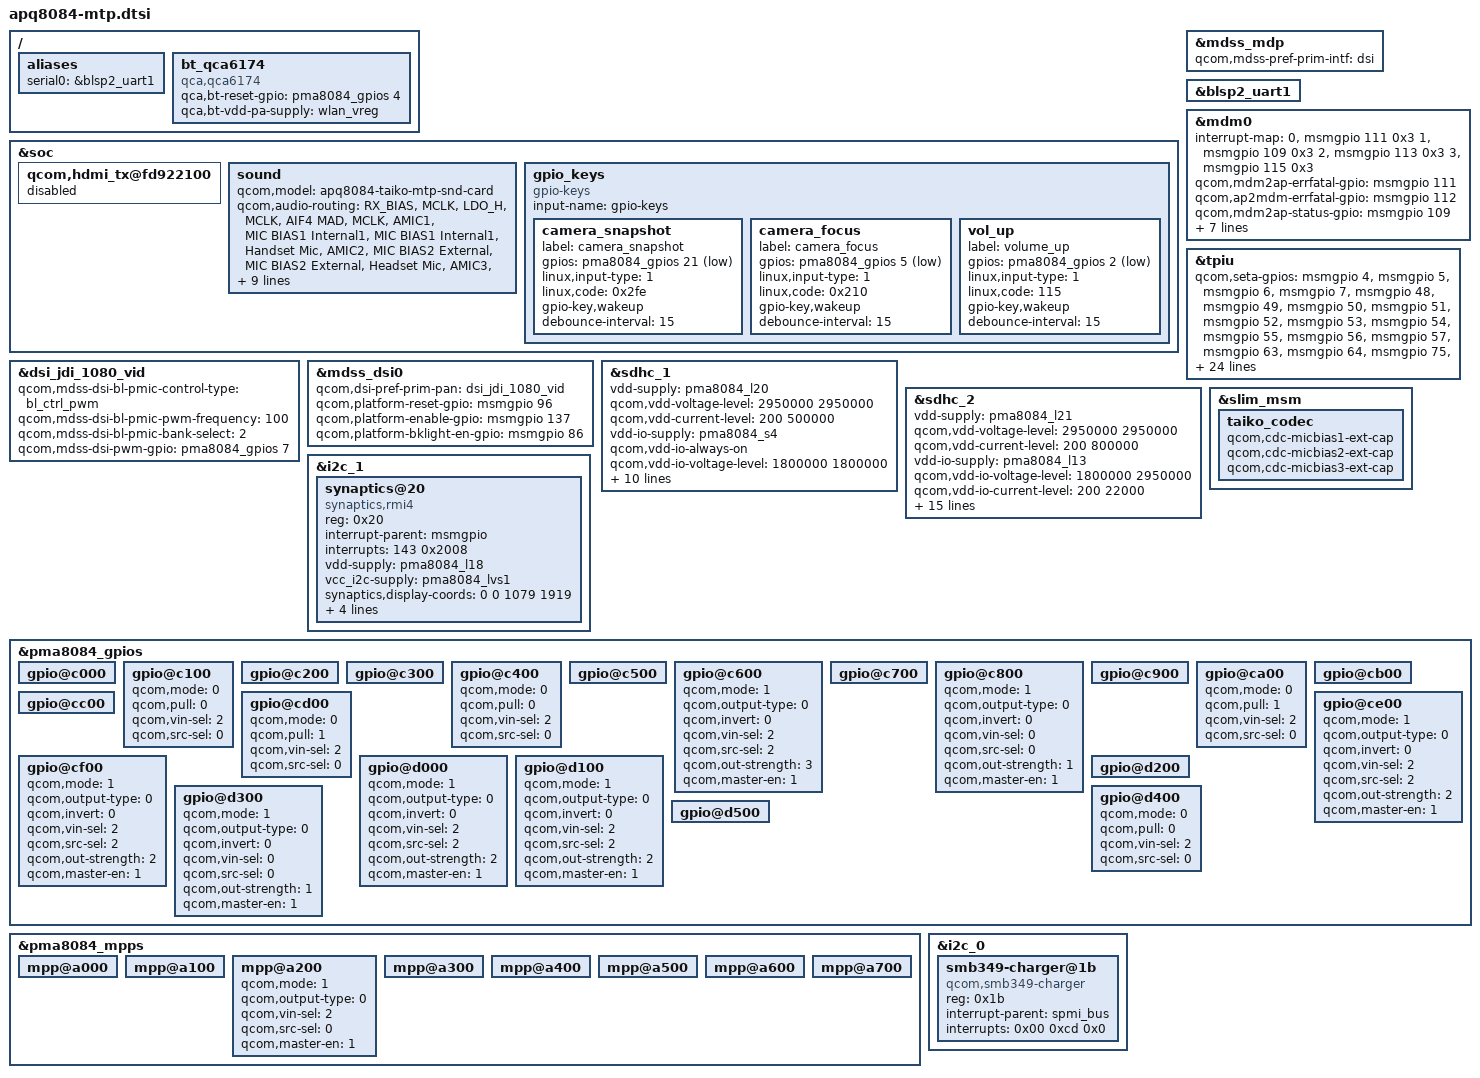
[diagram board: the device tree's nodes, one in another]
/* Copyright (c) 2013, The Linux Foundation. All rights reserved.
 *
 * This program is free software; you can redistribute it and/or modify
 * it under the terms of the GNU General Public License version 2 and
 * only version 2 as published by the Free Software Foundation.
 *
 * This program is distributed in the hope that it will be useful,
 * but WITHOUT ANY WARRANTY; without even the implied warranty of
 * MERCHANTABILITY or FITNESS FOR A PARTICULAR PURPOSE.  See the
 * GNU General Public License for more details.
 */

/include/ "external-mdm9x25.dtsi"

/ {
	aliases {
		serial0 = &blsp2_uart1;
	};

	bt_qca6174 {
		compatible = "qca,qca6174";
		qca,bt-reset-gpio = <&pma8084_gpios 4 0>; /* BT_EN */
		qca,bt-vdd-pa-supply = <&wlan_vreg>;
	};
};

&soc {
	qcom,hdmi_tx@fd922100 {
		status = "disabled";
	};

	sound {
		qcom,model = "apq8084-taiko-mtp-snd-card";

		qcom,audio-routing =
			"RX_BIAS", "MCLK",
			"LDO_H", "MCLK",
			"AIF4 MAD", "MCLK",
			"AMIC1", "MIC BIAS1 Internal1",
			"MIC BIAS1 Internal1", "Handset Mic",
			"AMIC2", "MIC BIAS2 External",
			"MIC BIAS2 External", "Headset Mic",
			"AMIC3", "MIC BIAS2 External",
			"MIC BIAS2 External", "ANCRight Headset Mic",
			"AMIC4", "MIC BIAS2 External",
			"MIC BIAS2 External", "ANCLeft Headset Mic",
			"DMIC1", "MIC BIAS1 External",
			"MIC BIAS1 External", "Digital Mic1",
			"DMIC3", "MIC BIAS3 External",
			"MIC BIAS3 External", "Digital Mic3";

		qcom,cdc-micbias2-headset-only;
		qcom,ext-mclk-gpio  = <&msmgpio 47 0>;
	};

	gpio_keys {
		compatible = "gpio-keys";
		input-name = "gpio-keys";

		camera_snapshot {
			label = "camera_snapshot";
			gpios = <&pma8084_gpios 21 0x1>;
			linux,input-type = <1>;
			linux,code = <0x2fe>;
			gpio-key,wakeup;
			debounce-interval = <15>;
		};

		camera_focus {
			label = "camera_focus";
			gpios = <&pma8084_gpios 5 0x1>;
			linux,input-type = <1>;
			linux,code = <0x210>;
			gpio-key,wakeup;
			debounce-interval = <15>;
		};

		vol_up {
			label = "volume_up";
			gpios = <&pma8084_gpios 2 0x1>;
			linux,input-type = <1>;
			linux,code = <115>;
			gpio-key,wakeup;
			debounce-interval = <15>;
		};
	};
};

/include/ "dsi-panel-jdi-1080p-video.dtsi"
&dsi_jdi_1080_vid {
	qcom,mdss-dsi-bl-pmic-control-type = "bl_ctrl_pwm";
	qcom,mdss-dsi-bl-pmic-pwm-frequency = <100>;
	qcom,mdss-dsi-bl-pmic-bank-select = <2>;
	qcom,mdss-dsi-pwm-gpio = <&pma8084_gpios 7 0>;
};

&mdss_mdp {
	qcom,mdss-pref-prim-intf = "dsi";
};

&mdss_dsi0 {
	qcom,dsi-pref-prim-pan = <&dsi_jdi_1080_vid>;
	qcom,platform-reset-gpio = <&msmgpio 96 0>;
	qcom,platform-enable-gpio = <&msmgpio 137 0>;
	qcom,platform-bklight-en-gpio = <&msmgpio 86 0>;
};

&blsp2_uart1 {
	status = "ok";
};

&mdm0 {
	interrupt-map = <0 &msmgpio 111 0x3
			1 &msmgpio 109 0x3
			2 &msmgpio 113 0x3
			3 &msmgpio 115 0x3>;
	qcom,mdm2ap-errfatal-gpio = <&msmgpio 111 0x00>;
	qcom,ap2mdm-errfatal-gpio = <&msmgpio 112 0x00>;
	qcom,mdm2ap-status-gpio   = <&msmgpio 109 0x00>;
	qcom,ap2mdm-status-gpio   = <&msmgpio 110 0x00>;
	qcom,ap2mdm-soft-reset-gpio = <&msmgpio 128 0x00>;
	qcom,mdm2ap-pblrdy-gpio = <&msmgpio 113 0x00>;
	qcom,ap2mdm-wakeup-gpio = <&msmgpio 108 0x00>;
	qcom,ap2mdm-vddmin-gpio = <&msmgpio 114 0x00>;
	qcom,mdm2ap-vddmin-gpio = <&msmgpio 115 0x00>;
	qcom,ap2mdm-chnlrdy-gpio = <&msmgpio 106 0x00>;
	status = "ok";
};

/* CoreSight */
&tpiu {
	qcom,seta-gpios = <&msmgpio 4 0>,
			  <&msmgpio 5 0>,
			  <&msmgpio 6 0>,
			  <&msmgpio 7 0>,
			  <&msmgpio 48 0>,
			  <&msmgpio 49 0>,
			  <&msmgpio 50 0>,
			  <&msmgpio 51 0>,
			  <&msmgpio 52 0>,
			  <&msmgpio 53 0>,
			  <&msmgpio 54 0>,
			  <&msmgpio 55 0>,
			  <&msmgpio 56 0>,
			  <&msmgpio 57 0>,
			  <&msmgpio 63 0>,
			  <&msmgpio 64 0>,
			  <&msmgpio 75 0>,
			  <&msmgpio 122 0>;
	qcom,seta-gpios-func = <4 4 4 4 5 4 4 5 5 4 4 4 4 4 4 5 2 1>;
	qcom,seta-gpios-drv =  <7 7 7 7 7 7 7 7 7 7 7 7 7 7 7 7 7 7>;
	qcom,seta-gpios-pull = <0 0 0 0 0 0 0 0 0 0 0 0 0 0 0 0 0 0>;
	qcom,seta-gpios-dir =  <2 2 2 2 2 2 2 2 2 2 2 2 2 2 2 2 2 2>;

	qcom,setb-gpios = <&msmgpio 10 0>,
			  <&msmgpio 11 0>,
			  <&msmgpio 29 0>,
			  <&msmgpio 30 0>,
			  <&msmgpio 39 0>,
			  <&msmgpio 40 0>,
			  <&msmgpio 43 0>,
			  <&msmgpio 44 0>,
			  <&msmgpio 45 0>,
			  <&msmgpio 46 0>,
			  <&msmgpio 67 0>,
			  <&msmgpio 68 0>,
			  <&msmgpio 69 0>,
			  <&msmgpio 70 0>,
			  <&msmgpio 71 0>,
			  <&msmgpio 72 0>,
			  <&msmgpio 102 0>,
			  <&msmgpio 121 0>;
	qcom,setb-gpios-func = <4 4 5 4 4 4 4 4 4 4 3 3 2 4 3 3 2 1>;
	qcom,setb-gpios-drv =  <7 7 7 7 7 7 7 7 7 7 7 7 7 7 7 7 7 7>;
	qcom,setb-gpios-pull = <0 0 0 0 0 0 0 0 0 0 0 0 0 0 0 0 0 0>;
	qcom,setb-gpios-dir =  <2 2 2 2 2 2 2 2 2 2 2 2 2 2 2 2 2 2>;
};

&sdhc_1 {
	vdd-supply = <&pma8084_l20>;
	qcom,vdd-voltage-level = <2950000 2950000>;
	qcom,vdd-current-level = <200 500000>;

	vdd-io-supply = <&pma8084_s4>;
	qcom,vdd-io-always-on;
	qcom,vdd-io-voltage-level = <1800000 1800000>;
	qcom,vdd-io-current-level = <200 154000>;

	qcom,pad-pull-on = <0x0 0x3 0x3 0x1>; /* no-pull, pull-up, pull-up, pull-down */
	qcom,pad-pull-off = <0x0 0x3 0x3 0x1>; /* no-pull, pull-up, pull-up, pull-down */
	qcom,pad-drv-on = <0x7 0x4 0x4>; /* 16mA, 10mA, 10mA */
	qcom,pad-drv-off = <0x0 0x0 0x0>; /* 2mA, 2mA, 2mA */

	qcom,clk-rates = <400000 20000000 25000000 50000000 100000000 200000000 400000000>;
	qcom,nonremovable;
	qcom,bus-speed-mode = "HS400_1p8v", "HS200_1p8v", "DDR_1p8v";
	status = "ok";
};

&sdhc_2 {
	vdd-supply = <&pma8084_l21>;
	qcom,vdd-voltage-level = <2950000 2950000>;
	qcom,vdd-current-level = <200 800000>;

	vdd-io-supply = <&pma8084_l13>;
	qcom,vdd-io-voltage-level = <1800000 2950000>;
	qcom,vdd-io-current-level = <200 22000>;

	qcom,pad-pull-on = <0x0 0x3 0x3>; /* no-pull, pull-up, pull-up */
	qcom,pad-pull-off = <0x0 0x3 0x3>; /* no-pull, pull-up, pull-up */
	qcom,pad-drv-on = <0x7 0x4 0x4>; /* 16mA, 10mA, 10mA */
	qcom,pad-drv-off = <0x0 0x0 0x0>; /* 2mA, 2mA, 2mA */

	qcom,clk-rates = <400000 20000000 25000000 50000000 100000000 200000000>;
	qcom,bus-speed-mode = "SDR12", "SDR25", "SDR50", "DDR50", "SDR104";

	#address-cells = <0>;
	interrupt-parent = <&sdhc_2>;
	interrupts = <0 1 2>;
	#interrupt-cells = <1>;
	interrupt-map-mask = <0xffffffff>;
	interrupt-map = <0 &intc 0 125 0
			1 &intc 0 221 0
			2 &msmgpio 122 0x3>;
	interrupt-names = "hc_irq", "pwr_irq", "status_irq";
	cd-gpios = <&msmgpio 122 0x1>;
	wp-gpios = <&msmgpio 75 0x1>;

	status = "ok";
};

&slim_msm {
	taiko_codec {
		qcom,cdc-micbias1-ext-cap;
		qcom,cdc-micbias2-ext-cap;
		qcom,cdc-micbias3-ext-cap;
	};
};

&i2c_1 {
	synaptics@20 {
		compatible = "synaptics,rmi4";
		reg = <0x20>;
		interrupt-parent = <&msmgpio>;
		interrupts = <143 0x2008>;
		vdd-supply = <&pma8084_l18>;
		vcc_i2c-supply = <&pma8084_lvs1>;
		synaptics,display-coords = <0 0 1079 1919>;
		synaptics,panel-coords = <0 0 1079 2084>;
		synaptics,reset-gpio = <&msmgpio 145 0x00>;
		synaptics,irq-gpio = <&msmgpio 143 0x2008>;
		synaptics,i2c-pull-up;
	};
};

&pma8084_gpios {
	gpio@c000 { /* GPIO 1 */
	};

	gpio@c100 { /* GPIO 2 */
		qcom,mode = <0>;
		qcom,pull = <0>;
		qcom,vin-sel = <2>;
		qcom,src-sel = <0>;
	};

	gpio@c200 { /* GPIO 3 */
	};

	gpio@c300 { /* GPIO 4 */
	};

	gpio@c400 { /* GPIO 5 */
		qcom,mode = <0>;
		qcom,pull = <0>;
		qcom,vin-sel = <2>;
		qcom,src-sel = <0>;
	};

	gpio@c500 { /* GPIO 6 */
	};

	gpio@c600 { /* GPIO 7 */
		/* Backlight PWM */
		qcom,mode = <1>;		/* Digital output */
		qcom,output-type = <0>;		/* CMOS logic */
		qcom,invert = <0>;		/* Do not invert the output */
		qcom,vin-sel = <2>;		/* PMA8084 S4 = 1.8 V */
		qcom,src-sel = <2>;		/* Special Function 1=LPG 3 */
		qcom,out-strength = <3>;	/* High drive strength */
		qcom,master-en = <1>;
	};

	gpio@c700 { /* GPIO 8 */
	};

	gpio@c800 { /* GPIO 9 */
		qcom,mode = <1>;		/* Digital output */
		qcom,output-type = <0>;		/* CMOS logic */
		qcom,invert = <0>;		/* Do not invert the output */
		qcom,vin-sel = <0>;		/* VPH_PWR */
		qcom,src-sel = <0>;		/* GPIO */
		qcom,out-strength = <1>;	/* High drive strength */
		qcom,master-en = <1>;		/* Enable GPIO */
	};

	gpio@c900 { /* GPIO 10 */
	};

	gpio@ca00 { /* GPIO 11 */
		/* VBUS interrupt */
		qcom,mode = <0>;
		qcom,pull = <1>;
		qcom,vin-sel = <2>;
		qcom,src-sel = <0>;
	};

	gpio@cb00 { /* GPIO 12 */
	};

	gpio@cc00 { /* GPIO 13 */
	};

	gpio@cd00 { /* GPIO 14 */
		qcom,mode = <0>;
		qcom,pull = <1>;
		qcom,vin-sel = <2>;
		qcom,src-sel = <0>;
	};

	gpio@ce00 { /* GPIO 15 */
		qcom,mode = <1>;		/* Digital output */
		qcom,output-type = <0>;		/* CMOS logic */
		qcom,invert = <0>;		/* Output low initially */
		qcom,vin-sel = <2>;		/* VIN 2 */
		qcom,src-sel = <2>;		/* Function 1 */
		qcom,out-strength = <2>;	/* Medium */
		qcom,master-en = <1>;		/* Enable GPIO */
	};

	gpio@cf00 { /* GPIO 16 */
		qcom,mode = <1>;		/* Digital output */
		qcom,output-type = <0>;		/* CMOS logic */
		qcom,invert = <0>;		/* Output low initially */
		qcom,vin-sel = <2>;		/* VIN 2 */
		qcom,src-sel = <2>;		/* Function 1 */
		qcom,out-strength = <2>;	/* Medium */
		qcom,master-en = <1>;		/* Enable GPIO */
	};

	gpio@d000 { /* GPIO 17 */
		qcom,mode = <1>;		/* Digital output */
		qcom,output-type = <0>;		/* CMOS logic */
		qcom,invert = <0>;		/* Output low initially */
		qcom,vin-sel = <2>;		/* VIN 2 */
		qcom,src-sel = <2>;		/* Function 1 */
		qcom,out-strength = <2>;	/* Medium */
		qcom,master-en = <1>;		/* Enable GPIO */
	};

	gpio@d100 { /* GPIO 18 */
		qcom,mode = <1>;		/* Digital output */
		qcom,output-type = <0>;		/* CMOS logic */
		qcom,invert = <0>;		/* Output low initially */
		qcom,vin-sel = <2>;		/* VIN 2 */
		qcom,src-sel = <2>;		/* Function 1 */
		qcom,out-strength = <2>;	/* Medium */
		qcom,master-en = <1>;		/* Enable GPIO */
	};

	gpio@d200 { /* GPIO 19 */
	};

	gpio@d300 { /* GPIO 20 */
		qcom,mode = <1>;		/* Digital output */
		qcom,output-type = <0>;		/* CMOS logic */
		qcom,invert = <0>;		/* Do not invert the output */
		qcom,vin-sel = <0>;		/* VPH_PWR */
		qcom,src-sel = <0>;		/* GPIO */
		qcom,out-strength = <1>;	/* High drive strength */
		qcom,master-en = <1>;		/* Enable GPIO */
	};

	gpio@d400 { /* GPIO 21 */
		qcom,mode = <0>;
		qcom,pull = <0>;
		qcom,vin-sel = <2>;
		qcom,src-sel = <0>;
	};

	gpio@d500 { /* GPIO 22 */
	};
};

&pma8084_mpps {
	mpp@a000 { /* MPP 1 */
	};

	mpp@a100 { /* MPP 2 */
	};

	mpp@a200 { /* MPP 3 */
		/* HDMI_5v_vreg regulator enable */
		qcom,mode = <1>;		/* Digital output */
		qcom,output-type = <0>;		/* CMOS logic */
		qcom,vin-sel = <2>;		/* VPH_PWR */
		qcom,src-sel = <0>;		/* Constant */
		qcom,master-en = <1>;		/* Enable GPIO */
	};

	mpp@a300 { /* MPP 4 */
	};

	mpp@a400 { /* MPP 5 */
	};

	mpp@a500 { /* MPP 6 */
	};

	mpp@a600 { /* MPP 7 */
	};

	mpp@a700 { /* MPP 8 */
	};
};

&i2c_0 {
	smb349-charger@1b {
		compatible = "qcom,smb349-charger";
		reg = <0x1b>;
		interrupt-parent = <&spmi_bus>;
		interrupts = <0x00 0xcd 0x0>; /* PMIC8084 GPIO 14 */
	};
};
